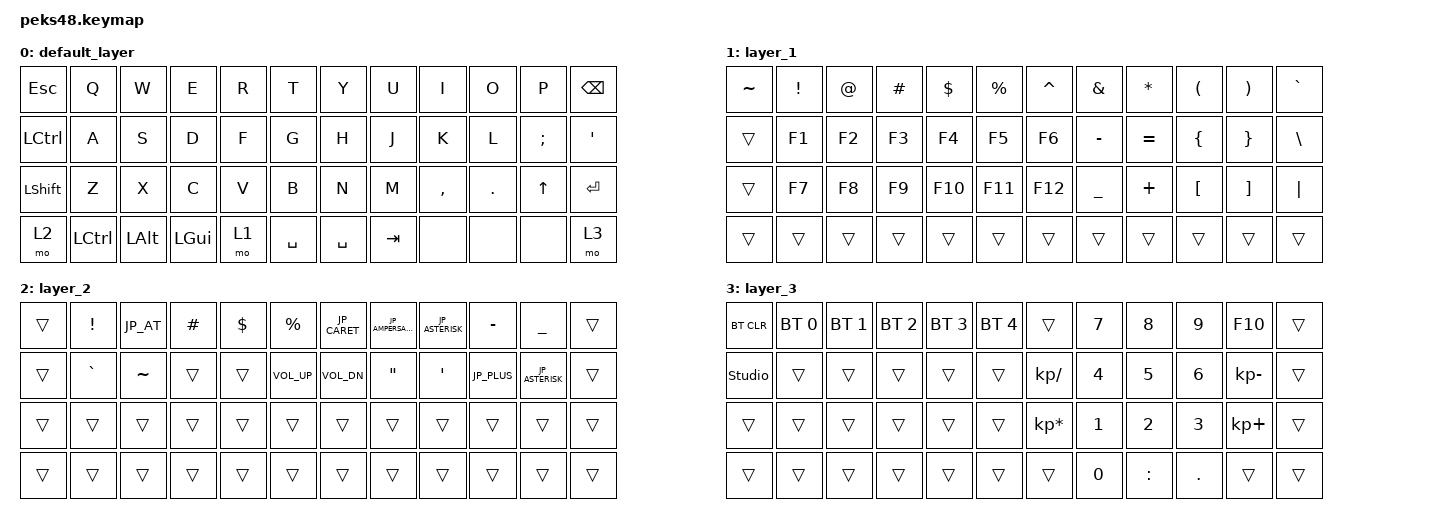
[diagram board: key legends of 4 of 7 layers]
#include <input/processors.dtsi>
#include <dt-bindings/zmk/input_transform.h>
#include <zephyr/dt-bindings/input/input-event-codes.h>
#include <behaviors.dtsi>
#include <dt-bindings/zmk/bt.h>
#include <dt-bindings/zmk/keys.h>
#include <dt-bindings/zmk/pointing.h>

// Conversion definition for using Japanese keyboard with OS settings
#define JP_DQUOTE       AT                // "
#define JP_AMPERSAND    CARET             // &
#define JP_QUOTE        AMPERSAND         // '
#define JP_EQUAL        UNDER             // =
#define JP_CARET        EQUAL             // ^
#define JP_YEN          0x89              // ¥
#define JP_PLUS         COLON             // +
#define JP_TILDE        PLUS              // ~
#define JP_PIPE         LS(0x89)          // |
#define JP_AT           LEFT_BRACKET      // @
#define JP_COLON        SINGLE_QUOTE      // :
#define JP_ASTERISK     DOUBLE_QUOTES     // *
#define JP_BACKQUOTE    LEFT_BRACE        // `
#define JP_UNDERSCORE   LS(0x87)          // _
#define JP_LBRACKET     RIGHT_BRACKET     // [
#define JP_RBRACKET     BACKSLASH         // ]
#define JP_LPAREN       ASTERISK          // (
#define JP_RPAREN       LEFT_PARENTHESIS  // )
#define JP_LBRACE       RIGHT_BRACE       // {
#define JP_RBRACE       PIPE              // }
#define JP_KANA         LANGUAGE_1        // かな
#define JP_EISU         LANGUAGE_2        // 英数
#define JP_HANZEN       GRAVE             // 半角/全角

&mt {
    flavor = "balanced";
    quick-tap-ms = <0>;
};

/ {

    keymap {
        compatible = "zmk,keymap";

        default_layer {
            bindings = <
&kp ESC     &kp Q      &kp W     &kp E     &kp R   &kp T         &kp Y      &kp U    &kp I      &kp O   &kp P          &kp BSPC 
&kp LCTRL   &kp A      &kp S     &kp D     &kp F   &kp G         &kp H      &kp J    &kp K      &kp L   &kp SEMICOLON  &kp SQT
&kp LSHIFT  &kp Z      &kp X     &kp C     &kp V   &kp B         &kp N      &kp M    &kp COMMA  &kp DOT &kp UP_ARROW   &kp RET
&mo 2       &kp LCTRL  &kp LALT  &kp LGUI  &mo 1   &kp SPACE     &kp SPACE  &kp TAB  &none      &none   &none          &mo 3
            >;
        };

        layer_1 {
            bindings = <
&kp TILDE  &kp EXCL  &kp AT  &kp HASH  &kp DLLR  &kp PRCNT  &kp CARET  &kp AMPS   &kp STAR   &kp LPAR  &kp RPAR   &kp GRAVE
&trans     &kp F1    &kp F2  &kp F3    &kp F4    &kp F5     &kp F6     &kp MINUS  &kp EQUAL  &kp LBRC  &kp RBRC   &kp BSLH
&trans     &kp F7    &kp F8  &kp F9    &kp F10   &kp F11    &kp F12    &kp UNDER  &kp PLUS   &kp LBKT  &kp RBKT   &kp PIPE
&trans     &trans    &trans  &trans    &trans    &trans     &trans     &trans     &trans     &trans    &trans     &trans
            >;
        };

        layer_2 {
            bindings = <
&trans  &kp EXCLAMATION  &kp JP_AT  &kp POUND  &kp DOLLAR  &kp PERCENT     &kp JP_CARET  &kp JP_AMPERSAND   &kp JP_ASTERISK   &kp MINUS    &kp UNDERSCORE   &trans
&trans  &kp GRAVE        &kp TILDE  &trans     &trans      &kp C_VOL_UP    &kp C_VOL_DN  &kp DOUBLE_QUOTES  &kp SINGLE_QUOTE  &kp JP_PLUS  &kp JP_ASTERISK  &trans
&trans  &trans           &trans     &trans     &trans      &trans          &trans        &trans             &trans            &trans       &trans           &trans
&trans  &trans           &trans     &trans     &trans      &trans          &trans        &trans             &trans            &trans       &trans           &trans
            >;
        };

        layer_3 {
            bindings = <
&bt BT_CLR      &bt BT_SEL 0  &bt BT_SEL 1  &bt BT_SEL 2  &bt BT_SEL 3    &bt BT_SEL 4   &trans          &kp N7  &kp N8      &kp N9   &kp F10      &trans
&studio_unlock  &trans        &trans        &trans        &trans          &trans         &kp KP_DIVIDE   &kp N4  &kp N5      &kp N6   &kp KP_MINUS &trans
&trans          &trans        &trans        &trans        &trans          &trans         &kp KP_MULTIPLY &kp N1  &kp N2      &kp N3   &kp KP_PLUS  &trans
&trans          &trans        &trans        &trans        &trans          &trans         &trans          &kp N0  &kp COLON   &kp DOT  &trans       &trans
            >;
        };

        layer_4 {
            bindings = <
&trans  &trans  &trans  &trans  &trans  &trans    &trans  &trans  &trans    &kp UP  &trans  &trans
&trans  &trans  &trans  &trans  &trans  &trans    &trans  &trans  &kp LEFT  &kp RIGHT  &trans  &trans
&trans  &trans  &trans  &trans  &trans  &trans    &trans  &trans  &kp DOWN  &trans  &trans  &trans
                                &trans  &trans    &trans  &trans
            >;
        };

        layer_5 {
            bindings = <
&trans  &trans  &trans    &trans    &trans    &trans    &trans  &trans    &trans    &trans    &trans  &trans
&trans  &trans  &mkp MB3  &mkp MB2  &mkp MB1  &trans    &trans  &mkp MB1  &mkp MB2  &mkp MB3  &trans  &trans
&trans  &trans  &trans    &trans    &trans    &trans    &trans  &trans    &trans    &trans    &trans  &trans
                                    &trans    &trans    &trans  &trans
            >;
        };

        layer_6 {
            bindings = <
&trans  &trans  &trans  &trans  &trans  &trans    &trans  &trans  &trans    &trans    &trans    &trans
&trans  &trans  &trans  &trans  &trans  &trans    &trans  &trans  &mkp MB1  &mkp MB3  &mkp MB2  &trans
&trans  &trans  &trans  &trans  &trans  &trans    &trans  &trans  &trans    &trans    &trans    &trans
                                &trans  &trans    &trans  &trans
            >;
        };
    };
};
